AUTOSAR XML (schema 00044)
package /ComponentTypes
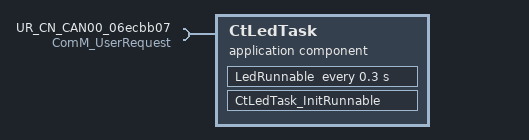
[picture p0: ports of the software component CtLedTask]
  application sw component type CtLedTask
    require port UR_CN_CAN00_06ecbb07: required-com-specs=[RequestComMode, GetCurrentComMode, GetMaxComMode, GetRequestedComMode], required-interface=ComM_UserRequest
    behavior CtLedTask_InternalBehavior
      timing event TMT_LedRunnable: start-on-event=LedRunnable, period=0.3
      init event CtLedTask_InitEvent: start-on-event=CtLedTask_InitRunnable
      runnable LedRunnable
      runnable CtLedTask_InitRunnable
        4 x sync call:
          SC_UR_CN_CAN00_06ecbb07_GetCurrentComMode: operation=UR_CN_CAN00_06ecbb07.GetCurrentComMode
          SC_UR_CN_CAN00_06ecbb07_GetMaxComMode: operation=UR_CN_CAN00_06ecbb07.GetMaxComMode
          SC_UR_CN_CAN00_06ecbb07_GetRequestedComMode: operation=UR_CN_CAN00_06ecbb07.GetRequestedComMode
          SC_UR_CN_CAN00_06ecbb07_RequestComMode: operation=UR_CN_CAN00_06ecbb07.RequestComMode
  swc implementation CtLedTask_Implementation: behavior=CtLedTask_InternalBehavior
